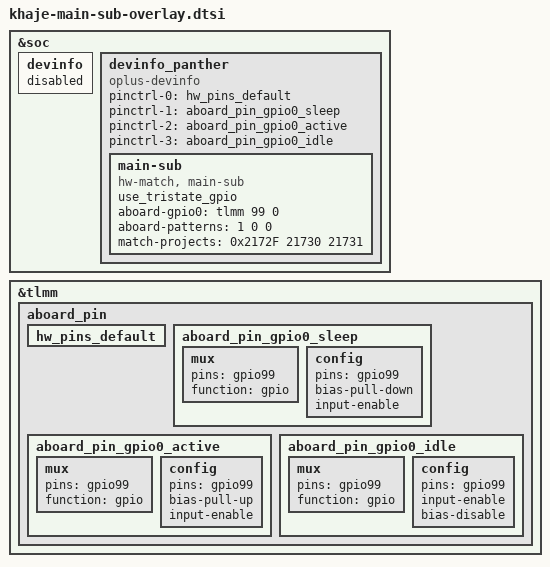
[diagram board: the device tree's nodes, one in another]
&soc {
	devinfo {
		 status = "disabled";
		};
	devinfo_panther {
		compatible = "oplus-devinfo";
		pinctrl-names = "default", "sleep", "active", "idle";
		pinctrl-0 = <&hw_pins_default>;
		pinctrl-1 = <&aboard_pin_gpio0_sleep>;
		pinctrl-2 = <&aboard_pin_gpio0_active>;
		pinctrl-3 = <&aboard_pin_gpio0_idle>;
		main-sub {
			use_tristate_gpio;
			compatible = "hw-match, main-sub";
			aboard-gpio0 = <&tlmm 99 0>;
			aboard-patterns = <1 0 0>;    /*0[high-resistance] 1[pull-down] 2[pull-up]*/
			/*main board*/
			match-projects = <0x2172F 21730 21731>;
		 };
	};
};
&tlmm {
	aboard_pin {
			hw_pins_default:hw_pins_default {
		};

		aboard_pin_gpio0_sleep:aboard_pin_gpio0_sleep {
			mux {
				pins = "gpio99";
				function = "gpio";
			};
			config {
				pins = "gpio99";
	                        bias-pull-down;
        	                input-enable;
			};
		};
		aboard_pin_gpio0_active:aboard_pin_gpio0_active {
			mux {
				pins = "gpio99";
				function = "gpio";
			};
			config {
				pins = "gpio99";
	                  	bias-pull-up;
                       	 	input-enable;
			};
		};

                aboard_pin_gpio0_idle:aboard_pin_gpio0_idle {
			mux {
				pins = "gpio99";
				function = "gpio";
			};
			config {
				pins = "gpio99";
				input-enable;
				bias-disable;
			};
		};
	};
};
